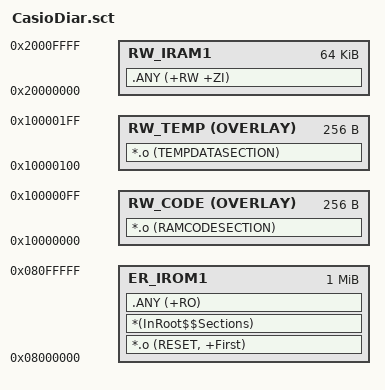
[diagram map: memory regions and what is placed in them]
; *************************************************************
; *** Scatter-Loading Description File generated by uVision ***
; *************************************************************

LR_IROM1 0x08000000 0x00100000  {    ; load region size_region
  ER_IROM1 0x08000000 0x00100000  {  ; load address = execution address
   *.o (RESET, +First)
   *(InRoot$$Sections)
   .ANY (+RO)
  }
;  RW_IRAM1 0x20000000 0x00018000  {  ; RW data
   RW_IRAM1 0x20000000 0x00010000  {  ; RW data 65536
   .ANY (+RW +ZI)
  }
  RW_CODE 0x10000000 OVERLAY 0x00000100  {  ; RW data 256
   *.o (RAMCODESECTION)
  }
;  RW_TEMP 0x2000B000 OVERLAY 0x00001000  {  ; RW data
   RW_TEMP 0x10000100 OVERLAY 0x00000100  {  ; RW data
   *.o (TEMPDATASECTION)
  }
}

